AUTOSAR XML (schema 314)
package /ComponentType
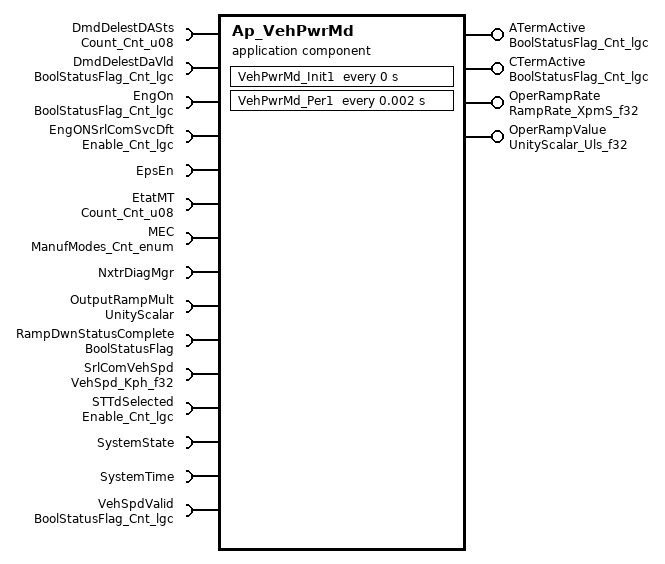
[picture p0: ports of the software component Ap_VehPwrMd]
  application software component type Ap_VehPwrMd
    4 x provide port:
      ATermActive: unqueued-sender-com-spec{data-element=Cnt_lgc, can-invalidate=false, init-value=D_TRUE_CNT_LGC}, provided-interface=BoolStatusFlag_Cnt_lgc
      CTermActive: unqueued-sender-com-spec{data-element=Cnt_lgc, can-invalidate=false, init-value=D_FALSE_CNT_LGC}, provided-interface=BoolStatusFlag_Cnt_lgc
      OperRampRate: unqueued-sender-com-spec{data-element=XpmS_f32, can-invalidate=false, init-value=D_ZERO_ULS_F32}, provided-interface=RampRate_XpmS_f32
      OperRampValue: unqueued-sender-com-spec{data-element=Uls_f32, can-invalidate=false, init-value=D_ZERO_ULS_F32}, provided-interface=UnityScalar_Uls_f32
    15 x require port:
      DmdDelestDASts: unqueued-receiver-com-spec{data-element=Cnt_u08, init-value=D_ZERO_CNT_U8}, required-interface=Count_Cnt_u08
      DmdDelestDaVld: unqueued-receiver-com-spec{data-element=Cnt_lgc, init-value=D_FALSE_CNT_LGC}, required-interface=BoolStatusFlag_Cnt_lgc
      EngOn: unqueued-receiver-com-spec{data-element=Cnt_lgc, init-value=D_FALSE_CNT_LGC}, required-interface=BoolStatusFlag_Cnt_lgc
      EngONSrlComSvcDft: unqueued-receiver-com-spec{data-element=Cnt_lgc, init-value=D_FALSE_CNT_LGC}, required-interface=Enable_Cnt_lgc
      EpsEn: client-com-spec=OP_GET, required-interface=EpsEn
      EtatMT: unqueued-receiver-com-spec{data-element=Cnt_u08, init-value=D_ZERO_CNT_U8}, required-interface=Count_Cnt_u08
      MEC: unqueued-receiver-com-spec{data-element=Cnt_enum, init-value=D_MANUFMODEINIT_CNT_ENUM}, required-interface=ManufModes_Cnt_enum
      NxtrDiagMgr: required-com-specs=[GetNTCActive, GetNTCFailed, GetNTCStatus, SetNTCStatus], required-interface=NxtrDiagMgr
      OutputRampMult: unqueued-receiver-com-spec{data-element=Uls_f32, init-value=D_ZERO_ULS_F32}, required-interface=UnityScalar
      RampDwnStatusComplete: unqueued-receiver-com-spec{data-element=Cnt_lgc, init-value=D_FALSE_CNT_LGC}, required-interface=BoolStatusFlag
      SrlComVehSpd: unqueued-receiver-com-spec{data-element=Kph_f32, init-value=D_ZERO_ULS_F32}, required-interface=VehSpd_Kph_f32
      STTdSelected: unqueued-receiver-com-spec{data-element=Cnt_lgc, init-value=D_FALSE_CNT_LGC}, required-interface=Enable_Cnt_lgc
      SystemState: required-interface=SystemState
      SystemTime: required-interface=SystemTime
        required-com-specs:
          DtrmnElapsedTime_mS_u16
          DtrmnElapsedTime_mS_u32
          DtrmnElapsedTime_uS_u16
          DtrmnElapsedTime_uS_u32
          GetSystemTime_mS_u32
          GetSystemTime_uS_u32
      VehSpdValid: unqueued-receiver-com-spec{data-element=Cnt_lgc, init-value=D_FALSE_CNT_LGC}, required-interface=BoolStatusFlag_Cnt_lgc
  internal behavior Ap_VehPwrMd_InternalBehavior: component=Ap_VehPwrMd
    timing event VehPwrMd_Init1_InitEvent: start-on-event=VehPwrMd_Init1, period=0
    timing event TMT_VehPwrMd_Per1: start-on-event=VehPwrMd_Per1, period=0.002
    port-api-options:
      enable-take-address=false, indirect-api=false, port=ATermActive
      enable-take-address=false, indirect-api=false, port=CTermActive
      enable-take-address=false, indirect-api=false, port=DmdDelestDASts
      enable-take-address=false, indirect-api=false, port=DmdDelestDaVld
      enable-take-address=false, indirect-api=false, port=EngOn
      enable-take-address=false, indirect-api=false, port=EngONSrlComSvcDft
      enable-take-address=false, indirect-api=false, port=EpsEn
      enable-take-address=false, indirect-api=false, port=EtatMT
      enable-take-address=false, indirect-api=false, port=MEC
      enable-take-address=false, indirect-api=false, port=NxtrDiagMgr
      enable-take-address=false, indirect-api=false, port=OperRampRate
      enable-take-address=false, indirect-api=false, port=OperRampValue
      enable-take-address=false, indirect-api=false, port=OutputRampMult
      enable-take-address=false, indirect-api=false, port=RampDwnStatusComplete
      enable-take-address=false, indirect-api=false, port=SrlComVehSpd
      enable-take-address=false, indirect-api=false, port=STTdSelected
      enable-take-address=false, indirect-api=false, port=SystemState
      enable-take-address=false, indirect-api=false, port=SystemTime
      enable-take-address=false, indirect-api=false, port=VehSpdValid
    runnable VehPwrMd_Init1
      data write access WRITE_OperRampRate_XpmS_f32: data-element=OperRampRate.XpmS_f32
      data write access WRITE_OperRampValue_Uls_f32: data-element=OperRampValue.Uls_f32
      sync call SC_SystemTime_GetSystemTime_mS_u32: operation=SystemTime.GetSystemTime_mS_u32, timeout=0
    runnable VehPwrMd_Per1
      11 x data read access:
        READ_DmdDelestDASts_Cnt_u08: data-element=DmdDelestDASts.Cnt_u08
        READ_DmdDelestDaVld_Cnt_lgc: data-element=DmdDelestDaVld.Cnt_lgc
        READ_EngOn_Cnt_lgc: data-element=EngOn.Cnt_lgc
        READ_EngONSrlComSvcDft_Cnt_lgc: data-element=EngONSrlComSvcDft.Cnt_lgc
        READ_EtatMT_Cnt_u08: data-element=EtatMT.Cnt_u08
        READ_MEC_Cnt_enum: data-element=MEC.Cnt_enum
        READ_OutputRampMult_Uls_f32: data-element=OutputRampMult.Uls_f32
        READ_RampDwnStatusComplete_Cnt_lgc: data-element=RampDwnStatusComplete.Cnt_lgc
        READ_SrlComVehSpd_Kph_f32: data-element=SrlComVehSpd.Kph_f32
        READ_STTdSelected_Cnt_lgc: data-element=STTdSelected.Cnt_lgc
        READ_VehSpdValid_Cnt_lgc: data-element=VehSpdValid.Cnt_lgc
      4 x data write access:
        WRITE_ATermActive_Cnt_lgc: data-element=ATermActive.Cnt_lgc
        WRITE_CTermActive_Cnt_lgc: data-element=CTermActive.Cnt_lgc
        WRITE_OperRampRate_XpmS_f32: data-element=OperRampRate.XpmS_f32
        WRITE_OperRampValue_Uls_f32: data-element=OperRampValue.Uls_f32
      4 x sync call, all with timeout=0:
        SC_EpsEn_OP_GET: operation=EpsEn.OP_GET
        SC_NxtrDiagMgr_GetNTCFailed: operation=NxtrDiagMgr.GetNTCFailed
        SC_SystemTime_DtrmnElapsedTime_mS_u16: operation=SystemTime.DtrmnElapsedTime_mS_u16
        SC_SystemTime_GetSystemTime_mS_u32: operation=SystemTime.GetSystemTime_mS_u32
  swc implementation Ap_VehPwrMd_Implementation: behavior=Ap_VehPwrMd_InternalBehavior
    code-descriptors:
      code Code: type=SRC
